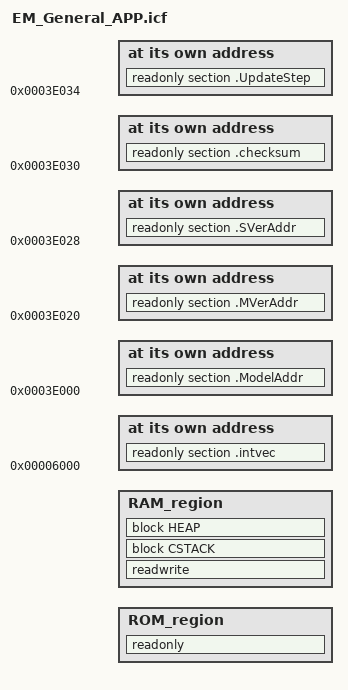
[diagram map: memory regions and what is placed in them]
/*###ICF### Section handled by ICF editor, don't touch! ****/
/*-Editor annotation file-*/
/* IcfEditorFile="$TOOLKIT_DIR$\config\ide\IcfEditor\cortex_v1_0.xml" */
/*-Specials-*/
define symbol __ICFEDIT_intvec_start__ = 0x000006000;
/*-Memory Regions-*/
define symbol __ICFEDIT_region_ROM_start__ = 0x00000006000;
define symbol __ICFEDIT_region_ROM_end__   = (0x00000000+0x00038000-1);
define symbol __ICFEDIT_region_RAM_start__ = 0x20000000;
define symbol __ICFEDIT_region_RAM_end__   = (0x20000000+0x00008000-1);
/*-Sizes-*/
define symbol __ICFEDIT_size_cstack__ = 0x1600;
define symbol __ICFEDIT_size_heap__   = 0x00;
/**** End of ICF editor section. ###ICF###*/

define memory mem with size = 4G;
define region ROM_region   = mem:[from __ICFEDIT_region_ROM_start__   to __ICFEDIT_region_ROM_end__];
define region RAM_region   = mem:[from __ICFEDIT_region_RAM_start__   to __ICFEDIT_region_RAM_end__];

define block CSTACK    with alignment = 8, size = __ICFEDIT_size_cstack__   { };
define block HEAP      with alignment = 8, size = __ICFEDIT_size_heap__     { };

///*add by ckm begin*/
//define region MYROM   = mem:[from __ICFEDIT_region_ROM_end__-0x400   to __ICFEDIT_region_ROM_end__];
//define block ExchangeText with size = 0x400, alignment = 4 { };
//place in RAM_region { block ExchangeText };
///*add by ckm end*/

initialize by copy { readwrite };
do not initialize  { section .noinit };

keep { section .intvec };
place at address mem:__ICFEDIT_intvec_start__ { readonly section .intvec };

/*add by ckm begin*/
place at address mem:0x0003e000 { readonly section .ModelAddr };
place at address mem:0x0003e020 { readonly section .MVerAddr };
place at address mem:0x0003e028 { readonly section .SVerAddr };
place at address mem:0x0003e030 { readonly section .checksum };
place at address mem:0x0003e034 { readonly section .UpdateStep };
/*add by ckm end*/

place in ROM_region   { readonly };
place in RAM_region   { readwrite,
                        block CSTACK, 
                        block HEAP };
